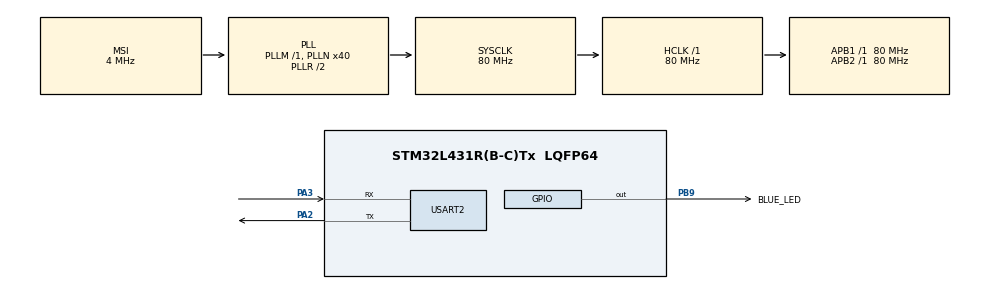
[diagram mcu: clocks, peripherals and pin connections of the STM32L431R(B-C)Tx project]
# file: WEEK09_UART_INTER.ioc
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Mcu.Family=STM32L4
Mcu.Name=STM32L431R(B-C)Tx
Mcu.Package=LQFP64
NVIC.PriorityGroup=NVIC_PRIORITYGROUP_4
NVIC.TIM6_DAC_IRQn=true\:0\:0\:false\:false\:true\:true\:true\:true
NVIC.USART2_IRQn=true\:0\:0\:false\:false\:true\:true\:true\:true
PA13\ (JTMS-SWDIO).Mode=Serial_Wire
PA13\ (JTMS-SWDIO).Signal=SYS_JTMS-SWDIO
PA14\ (JTCK-SWCLK).Mode=Serial_Wire
PA14\ (JTCK-SWCLK).Signal=SYS_JTCK-SWCLK
PA2.Mode=Asynchronous
PA2.Signal=USART2_TX
PA3.Mode=Asynchronous
PA3.Signal=USART2_RX
PB9.GPIO_Label=BLUE_LED
PB9.Signal=GPIO_Output
ProjectManager.HeapSize=0x200
ProjectManager.StackSize=0x400
ProjectManager.TargetToolchain=MDK-ARM V5.32
RCC.AHBFreq_Value=80000000
RCC.APB1Freq_Value=80000000
RCC.APB1TimFreq_Value=80000000
RCC.APB2Freq_Value=80000000
RCC.APB2TimFreq_Value=80000000
RCC.CortexFreq_Value=80000000
RCC.HCLKFreq_Value=80000000
RCC.HSE_VALUE=8000000
RCC.HSI48_VALUE=48000000
RCC.HSI_VALUE=16000000
RCC.LSE_VALUE=32768
RCC.MSI_VALUE=4000000
RCC.PLLN=40
RCC.SYSCLKFreq_VALUE=80000000
RCC.SYSCLKSource=RCC_SYSCLKSOURCE_PLLCLK
RCC.VCOOutputFreq_Value=160000000
USART2.VirtualMode-Asynchronous=VM_ASYNC
VP_TIM6_VS_ClockSourceINT.Mode=Enable_Timer
board=custom

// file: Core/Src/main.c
/* USER CODE BEGIN Header */
/**
  ******************************************************************************
  * @file           : main.c
  * @brief          : Main program body
  ******************************************************************************
  * @attention
  *
  * Copyright (c) 2022 STMicroelectronics.
  * All rights reserved.
  *
  * This software is licensed under terms that can be found in the LICENSE file
  * in the root directory of this software component.
  * If no LICENSE file comes with this software, it is provided AS-IS.
  *
  ******************************************************************************
  */
/* USER CODE END Header */
#include "main.h"
#include "tim.h"
#include "usart.h"
#include "gpio.h"

/* USER CODE BEGIN Includes */
#include "stdio.h"
#include "string.h"
/* USER CODE END Includes */

/* USER CODE BEGIN PV */
uint8_t rData;
uint8_t tData[255];
uint8_t shaking[7] = "SHAKING";
uint8_t light_on[2] = "ON";
uint8_t light_off[3] = "OFF";
int count = 0;
int flag = 1;
/* USER CODE END PV */

void SystemClock_Config(void);

/* USER CODE BEGIN 0 */
void HAL_UART_RxCpltCallback(UART_HandleTypeDef *huart)
{
	HAL_UART_Transmit(&huart2, &rData, sizeof(rData), 0);
	HAL_UART_Receive_IT(&huart2, &rData, 1);
	tData[count++] = rData;
}

/**
* compare the string.
*
* @param source a array of the uart receive to pc.
* @param target a array of the string that is being compared with the source array.
* @retval if the two strings are completely equal, the function will return a 0, else return a -1.
* @author zhengrenfu
*/
int compareString(uint8_t source[], uint8_t target[], int size) {
	int matched = 0;

	for (int i = 0; i < size; i++) {
		if (source[i] == target[i]) matched++;
	}

	if (matched == size) {
		// printf("[v]rx/tx matched successfully, the times is %d", matched);
		return 0;
	} else {
		// printf("[x]rx/tx failed to match, the times is %d", matched);
		return -1;
	}
}
/* USER CODE END 0 */

int main(void)
{

  /* MCU Configuration--------------------------------------------------------*/

  /* Reset of all peripherals, Initializes the Flash interface and the Systick. */
  HAL_Init();

  /* Configure the system clock */
  SystemClock_Config();

  /* Initialize all configured peripherals */
  MX_GPIO_Init();
  MX_USART2_UART_Init();
  MX_TIM6_Init();
  /* USER CODE BEGIN 2 */
	HAL_UART_Receive_IT(&huart2, &rData, 1);

  /* USER CODE END 2 */

  /* Infinite loop */
  while (1)
  {
		HAL_Delay(100);

		if (compareString(tData, shaking, sizeof(shaking)) == 0) {
			flag = 0;
		} else if (compareString(tData, light_on, sizeof(light_on)) == 0) {
			// printf("light is on, flag => %d", flag);
			HAL_GPIO_WritePin(BLUE_LED_GPIO_Port, BLUE_LED_Pin, GPIO_PIN_RESET);
			flag = 1;
		} else if (compareString(tData, light_off, sizeof(light_off)) == 0) {
			// printf("light is off, flag => %d", flag);
			HAL_GPIO_WritePin(BLUE_LED_GPIO_Port, BLUE_LED_Pin, GPIO_PIN_SET);
			flag = 1;
		}

		if (flag == 0) {
			// printf("shaking the light, flag => %d", flag);
			HAL_GPIO_WritePin(BLUE_LED_GPIO_Port, BLUE_LED_Pin, GPIO_PIN_SET);
			HAL_Delay(1000);
			HAL_GPIO_WritePin(BLUE_LED_GPIO_Port, BLUE_LED_Pin, GPIO_PIN_RESET);
			HAL_Delay(1000);
		}

		count = 0;
		memset(&tData, 0, 255);
  }
}

void SystemClock_Config(void)
{
  RCC_OscInitTypeDef RCC_OscInitStruct = {0};
  RCC_ClkInitTypeDef RCC_ClkInitStruct = {0};

  /** Configure the main internal regulator output voltage
  */
  if (HAL_PWREx_ControlVoltageScaling(PWR_REGULATOR_VOLTAGE_SCALE1) != HAL_OK)
  {
    Error_Handler();
  }

  /** Initializes the RCC Oscillators according to the specified parameters
  * in the RCC_OscInitTypeDef structure.
  */
  RCC_OscInitStruct.OscillatorType = RCC_OSCILLATORTYPE_MSI;
  RCC_OscInitStruct.MSIState = RCC_MSI_ON;
  RCC_OscInitStruct.MSICalibrationValue = 0;
  RCC_OscInitStruct.MSIClockRange = RCC_MSIRANGE_6;
  RCC_OscInitStruct.PLL.PLLState = RCC_PLL_ON;
  RCC_OscInitStruct.PLL.PLLSource = RCC_PLLSOURCE_MSI;
  RCC_OscInitStruct.PLL.PLLM = 1;
  RCC_OscInitStruct.PLL.PLLN = 40;
  RCC_OscInitStruct.PLL.PLLP = RCC_PLLP_DIV7;
  RCC_OscInitStruct.PLL.PLLQ = RCC_PLLQ_DIV2;
  RCC_OscInitStruct.PLL.PLLR = RCC_PLLR_DIV2;
  if (HAL_RCC_OscConfig(&RCC_OscInitStruct) != HAL_OK)
  {
    Error_Handler();
  }

  /** Initializes the CPU, AHB and APB buses clocks
  */
  RCC_ClkInitStruct.ClockType = RCC_CLOCKTYPE_HCLK|RCC_CLOCKTYPE_SYSCLK
                              |RCC_CLOCKTYPE_PCLK1|RCC_CLOCKTYPE_PCLK2;
  RCC_ClkInitStruct.SYSCLKSource = RCC_SYSCLKSOURCE_PLLCLK;
  RCC_ClkInitStruct.AHBCLKDivider = RCC_SYSCLK_DIV1;
  RCC_ClkInitStruct.APB1CLKDivider = RCC_HCLK_DIV1;
  RCC_ClkInitStruct.APB2CLKDivider = RCC_HCLK_DIV1;

  if (HAL_RCC_ClockConfig(&RCC_ClkInitStruct, FLASH_LATENCY_4) != HAL_OK)
  {
    Error_Handler();
  }
}

void Error_Handler(void)
{
  __disable_irq();
  while (1)
  {
  }
}
